# SF32LB57x register map
File version: 1.0
CPU: CM33 r0p1, little endian, MPU, FPU, 3 interrupt priority bits
Registers are 32-bit, read-write, reset 0x0 unless marked. A register's access mark holds for its fields unless they carry their own. Offsets are from the block's base; [hi:lo] are bit positions; {n}, {i} and the like mark numbered series.

## ATIM1
Base 0x50004000
Same registers: ATIM2 0x50005000
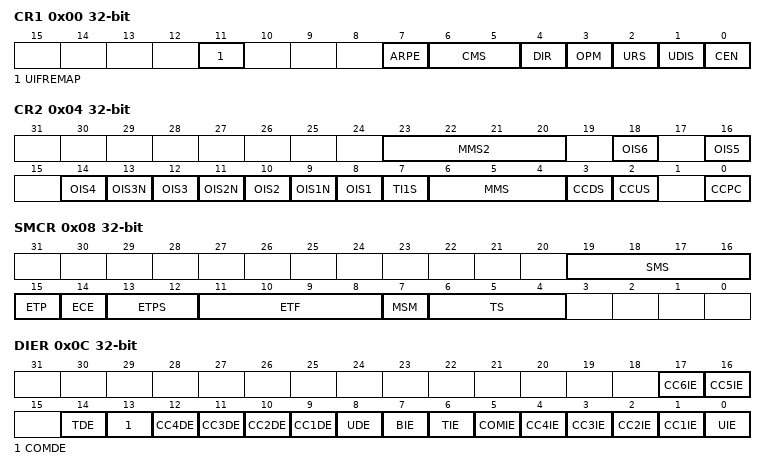
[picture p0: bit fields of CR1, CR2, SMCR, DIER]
0x00 CR1 — TIM control register 1
  [11] UIFREMAP — UIF status bit remapping 0: No remapping. UIF status bit is not copied to TIM_CNT register bit 31 1: Remapping enabled. UIF status bit is copied to TIM_CNT register bit 31.
  [7] ARPE — Auto-reload preload enable 0: TIMx_ARR register is not buffered 1: TIMx_ARR register is buffered
  [6:5] CMS — Center-aligned mode selection 00: Edge-aligned mode. The counter counts up or down depending on the direction bit (DIR). 01: Center-aligned mode 1. The counter counts up and down alternatively. Output compare interrupt flags of channels configured in output (CCxS=00 in TIMx_CCMRx register) are set only when the counter is counting down. 10: Center-aligned mode 2. The counter counts up and down alternatively. Output compare interrupt flags of channels configured in output (CCxS=00 in TIMx_CCMRx register) are set only when the counter is counting up. 11: Center-aligned mode 3. The counter counts up and down alternatively. Output compare interrupt flags of channels configured in output (CCxS=00 in TIMx_CCMRx register) are set both when the counter is counting up or down. Note: It is not allowed to switch from edge-aligned mode to center-aligned mode as long as the counter is enabled (CEN=1)
  [4] DIR — Direction 0: Counter used as upcounter 1: Counter used as downcounter
  [3] OPM — One-pulse mode 0: Counter is not stopped at update event 1: Counter stops counting at the next update event (clearing the bit CEN)
  [2] URS — Update request source This bit is set and cleared by software to select the UEV event sources. 0: Any of the following events generate an update interrupt or DMA request if enabled. These events can be: – Counter overflow/underflow – Setting the UG bit – Update generation through the slave mode controller 1: Only counter overflow/underflow generates an update interrupt or DMA request if enabled.
  [1] UDIS — Update disable This bit is set and cleared by software to enable/disable UEV event generation. 0: UEV enabled. The Update (UEV) event is generated by one of the following events: – Counter overflow/underflow – Setting the UG bit – Update generation through the slave mode controller Buffered registers are then loaded with their preload values. 1: UEV disabled. The Update event is not generated, shadow registers keep their value (ARR, PSC, CCRx). However the counter and the prescaler are reinitialized if the UG bit is set or if a hardware reset is received from the slave mode controller.
  [0] CEN — Counter enable 0: Counter disabled 1: Counter enabled Note: External clock, gated mode and encoder mode can work only if the CEN bit has been previously set by software. However trigger mode can set the CEN bit automatically by hardware. CEN is cleared automatically in one-pulse mode, when an update event occurs.
0x04 CR2 — TIM control register 2
  [23:20] MMS2 — Master mode selection 2 These bits allow the information to be sent to ADC for synchronization (TRGO2) to be selected. The combination is as follows: 0000: Reset - the UG bit from the TIMx_EGR register is used as trigger output (TRGO2). If the reset is generated by the trigger input (slave mode controller configured in reset mode), the signal on TRGO2 is delayed compared to the actual reset. 0001: Enable - the Counter Enable signal CNT_EN is used as trigger output (TRGO2). It is useful to start several timers at the same time or to control a window in which a slave timer is enabled. The Counter Enable signal is generated by a logic AND between the CEN control bit and the trigger input when configured in Gated mode. When the Counter Enable signal is controlled by the trigger input, there is a delay on TRGO2, except if the Master/Slave mode is selected (see the MSM bit description in TIMx_SMCR register). 0010: Update - the update event is selected as trigger output (TRGO2). For instance, a master timer can then be used as a prescaler for a slave timer. 0011: Compare pulse - the trigger output sends a positive pulse when the CC1IF flag is to be set (even if it was already high), as soon as a capture or compare match occurs (TRGO2). 0100: Compare - OC1REFC signal is used as trigger output (TRGO2) 0101: Compare - OC2REFC signal is used as trigger output (TRGO2) 0110: Compare - OC3REFC signal is used as trigger output (TRGO2) 0111: Compare - OC4REFC signal is used as trigger output (TRGO2) 1000: Compare - OC5REF signal is used as trigger output (TRGO2) 1001: Compare - OC6REF signal is used as trigger output (TRGO2) 1010: Compare Pulse - OC4REFC rising or falling edges generate pulses on TRGO2 1011: Compare Pulse - OC6REF rising or falling edges generate pulses on TRGO2 1100: Compare Pulse - OC4REFC or OC6REF rising edges generate pulses on TRGO2 1101: Compare Pulse - OC4REFC rising or OC6REF falling edges generate pulses on TRGO2 1110: Compare Pulse - OC5REF or OC6REF rising edges generate pulses on TRGO2 1111: Compare Pulse - OC5REF rising or OC6REF falling edges generate pulses on TRGO2
  [2n+6] OIS{n} (n=2..6) — Output Idle state {n} (OC{n} output)
  [13] OIS3N — Output Idle state 3 (OC3N output)
  [11] OIS2N — Output Idle state 2 (OC2N output)
  [9] OIS1N — Output Idle state 1 (OC1N output) 0: OC1N=0 after a dead-time when MOE=0 1: OC1N=1 after a dead-time when MOE=0 Note: This bit, as well as other OISxN, can not be modified as long as LOCK level 1, 2 or 3 has been programmed
  [8] OIS1 — Output Idle state 1 (OC1 output) 0: OC1=0 (after a dead-time if OC1N is implemented) when MOE=0 1: OC1=1 (after a dead-time if OC1N is implemented) when MOE=0 Note: This bit, as well as other OISx, can not be modified as long as LOCK level 1, 2 or 3 has been programmed
  [7] TI1S — TI1 selection 0: The TIMx_CH1 pin is connected to TI1 input 1: The TIMx_CH1, CH2 and CH3 pins are connected to the TI1 input (XOR combination)
  [6:4] MMS — Master mode selection These bits allow to select the information to be sent in master mode to slave timers for synchronization (TRGO). The combination is as follows: 000: Reset - the UG bit from the TIMx_EGR register is used as trigger output (TRGO). If the reset is generated by the trigger input (slave mode controller configured in reset mode) then the signal on TRGO is delayed compared to the actual reset. 001: Enable - the Counter enable signal, CNT_EN, is used as trigger output (TRGO). It is useful to start several timers at the same time or to control a window in which a slave timer is enabled. The Counter Enable signal is generated by a logic OR between CEN control bit and the trigger input when configured in gated mode. When the Counter Enable signal is controlled by the trigger input, there is a delay on TRGO, except if the master/slave mode is selected (see the MSM bit description in TIMx_SMCR register). 010: Update - The update event is selected as trigger output (TRGO). For instance a master timer can then be used as a prescaler for a slave timer. 011: Compare Pulse - The trigger output send a positive pulse when the CC1IF flag is to be set (even if it was already high), as soon as a capture or a compare match occurred. (TRGO) 100: Compare - OC1REFC signal is used as trigger output (TRGO) 101: Compare - OC2REFC signal is used as trigger output (TRGO) 110: Compare - OC3REFC signal is used as trigger output (TRGO) 111: Compare - OC4REFC signal is used as trigger output (TRGO) Note: The clock of the slave timer must be enabled prior to receive events from the master timer, and must not be changed on-the-fly while triggers are received from the master timer
  [3] CCDS — Capture/compare DMA selection 0: CCx DMA request sent when CCx event occurs 1: CCx DMA requests sent when update event occurs
  [2] CCUS — Capture/compare control update selection 0: When capture/compare control bits are preloaded (CCPC=1), they are updated by setting the COMG bit only 1: When capture/compare control bits are preloaded (CCPC=1), they are updated by setting the COMG bit or when an edge occurs on TRGI after Trigger selection Note: This bit acts only on channels that have a complementary output.
  [0] CCPC — Capture/compare preloaded control 0: CCxE, CCxNE and OCxM bits are not preloaded 1: CCxE, CCxNE and OCxM bits are preloaded, after having been written, they are updated only when a commutation event (COM) occurs (COMG bit set or edge detected on TRGI after Trigger selection, depending on the CCUS bit). Note: This bit acts only on channels that have a complementary output.
0x08 SMCR — TIM slave mode control register
  [19:16] SMS — Slave mode selection When external signals are selected the active edge of the trigger signal (TRGI) is linked to the polarity selected on the external input (see Input Control register and Control Register description. 0000: Slave mode disabled - if CEN = ‘1 then the prescaler is clocked directly by the internal clock. 0001: Encoder mode 1 - Counter counts up/down on TI1FP1 edge depending on TI2FP2 level. 0010: Encoder mode 2 - Counter counts up/down on TI2FP2 edge depending on TI1FP1 level. 0011: Encoder mode 3 - Counter counts up/down on both TI1FP1 and TI2FP2 edges depending on the level of the other input. 0100: Reset Mode - Rising edge of the selected trigger input (TRGI) reinitializes the counter and generates an update of the registers. 0101: Gated Mode - The counter clock is enabled when the trigger input (TRGI) is high. The counter stops (but is not reset) as soon as the trigger becomes low. Both start and stop of the counter are controlled. 0110: Trigger Mode - The counter starts at a rising edge of the trigger TRGI (but it is not reset). Only the start of the counter is controlled. 0111: External Clock Mode 1 - Rising edges of the selected trigger (TRGI) clock the counter. 1000: Combined reset + trigger mode - Rising edge of the selected trigger input (TRGI) reinitializes the counter, generates an update of the registers and starts the counter. Note: The gated mode must not be used if TI1F_ED is selected as the trigger input (TS=100). Indeed, TI1F_ED outputs 1 pulse for each transition on TI1F, whereas the gated mode checks the level of the trigger signal. Note: The clock of the slave peripherals (timer, ADC, ...) receiving the TRGO or the TRGO2 signals must be enabled prior to receive events from the master timer, and the clock frequency (prescaler) must not be changed on-the-fly while triggers are received from the master timer.
  [15] ETP — External trigger polarity This bit selects whether ETR or ETR is used for trigger operations 0: ETR is non-inverted, active at high level or rising edge 1: ETR is inverted, active at low level or falling edge
  [14] ECE — External clock enable This bit enables External clock mode 2. 0: External clock mode 2 disabled 1: External clock mode 2 enabled. The counter is clocked by any active edge on the ETRF signal. Note: 1: Setting the ECE bit has the same effect as selecting external clock mode 1 with TRGI connected to ETRF (SMS=111 and TS=111). 2: It is possible to simultaneously use external clock mode 2 with the following slave modes: reset mode, gated mode and trigger mode. Nevertheless, TRGI must not be connected to ETRF in this case (TS bits must not be 111). 3: If external clock mode 1 and external clock mode 2 are enabled at the same time, the external clock input is ETRF.
  [13:12] ETPS — External trigger prescaler External trigger signal ETRP frequency must be at most 1/4 of CK_INT frequency. A prescaler can be enabled to reduce ETRP frequency. It is useful when inputting fast external clocks. 00: Prescaler OFF 01: ETRP frequency divided by 2 10: ETRP frequency divided by 4 11: ETRP frequency divided by 8
  [11:8] ETF — External trigger filter This bit-field then defines the frequency used to sample ETRP signal and the length of the digital filter applied to ETRP. The digital filter is made of an event counter in which N consecutive events are needed to validate a transition on the output: 0000: No filter, sampling is done at fpclk 0001: fSAMPLING=fpclk, N=2 0010: fSAMPLING=fpclk, N=4 0011: fSAMPLING=fpclk, N=8 0100: fSAMPLING=fpclk/2, N=6 0101: fSAMPLING=fpclk/2, N=8 0110: fSAMPLING=fpclk/4, N=6 0111: fSAMPLING=fpclk/4, N=8 1000: fSAMPLING=fpclk/8, N=6 1001: fSAMPLING=fpclk/8, N=8 1010: fSAMPLING=fpclk/16, N=5 1011: fSAMPLING=fpclk/16, N=6 1100: fSAMPLING=fpclk/16, N=8 1101: fSAMPLING=fpclk/32, N=5 1110: fSAMPLING=fpclk/32, N=6 1111: fSAMPLING=fpclk/32, N=8
  [7] MSM — Master/Slave mode 0: No action 1: The effect of an event on the trigger input (TRGI) is delayed to allow a perfect synchronization between the current timer and its slaves (through TRGO). It is useful if we want to synchronize several timers on a single external event.
  [6:4] TS — Trigger selection This bit-field selects the trigger input to be used to synchronize the counter. 000: Internal Trigger 0 (ITR0) 001: Internal Trigger 1 (ITR1) 010: Internal Trigger 2 (ITR2) 011: Internal Trigger 3 (ITR3) 100: TI1 Edge Detector (TI1F_ED) 101: Filtered Timer Input 1 (TI1FP1) 110: Filtered Timer Input 2 (TI2FP2) 111: External Trigger input (ETRF) Note: These bits must be changed only when they are not used (e.g. when SMS=000) to avoid wrong edge detections at the transition.
0x0C DIER — TIM DMA/Interrupt enable register
  [17] CC6IE — Capture/Compare 6 interrupt enable 0: CC6 interrupt disabled. 1: CC6 interrupt enabled
  [16] CC5IE — Capture/Compare 5 interrupt enable 0: CC5 interrupt disabled. 1: CC5 interrupt enabled
  [14] TDE — Trigger DMA request enable 0: Trigger DMA request disabled. 1: Trigger DMA request enabled.
  [13] COMDE — COM DMA request enable 0: COM DMA request disabled 1: COM DMA request enabled
  [12] CC4DE — Capture/Compare 4 DMA request enable 0: CC4 DMA request disabled. 1: CC4 DMA request enabled
  [11] CC3DE — Capture/Compare 3 DMA request enable 0: CC3 DMA request disabled. 1: CC3 DMA request enabled.
  [10] CC2DE — Capture/Compare 2 DMA request enable 0: CC2 DMA request disabled. 1: CC2 DMA request enabled.
  [9] CC1DE — Capture/Compare 1 DMA request enable 0: CC1 DMA request disabled. 1: CC1 DMA request enabled.
  [8] UDE — Update DMA request enable 0: Update DMA request disabled. 1: Update DMA request enabled
  [7] BIE — Break interrupt enable 0: Break interrupt disabled 1: Break interrupt enabled
  [6] TIE — Trigger interrupt enable 0: Trigger interrupt disabled. 1: Trigger interrupt enabled
  [5] COMIE — COM interrupt enable 0: COM interrupt disabled 1: COM interrupt enabled
  [4] CC4IE — Capture/Compare 4 interrupt enable 0: CC4 interrupt disabled. 1: CC4 interrupt enabled
  [3] CC3IE — Capture/Compare 3 interrupt enable 0: CC3 interrupt disabled. 1: CC3 interrupt enabled
  [2] CC2IE — Capture/Compare 2 interrupt enable 0: CC2 interrupt disabled. 1: CC2 interrupt enabled.
  [1] CC1IE — Capture/Compare 1 interrupt enable 0: CC1 interrupt disabled. 1: CC1 interrupt enabled
  [0] UIE — Update interrupt enable 0: Update interrupt disabled. 1: Update interrupt enabled
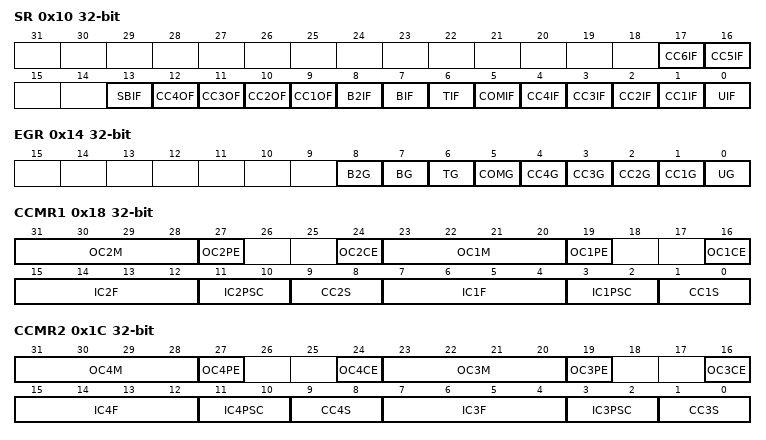
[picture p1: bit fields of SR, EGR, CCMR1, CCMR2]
0x10 SR — TIM status register
  [17] CC6IF — Compare 6 interrupt flag
  [16] CC5IF — Compare 5 interrupt flag
  [13] SBIF — System Break interrupt flag This flag is set by hardware as soon as the system break input goes active. It can be cleared by software if the system break input is not active. This flag must be reset to re-start PWM operation. 0: No break event occurred. 1: An active level has been detected on the system break input. An interrupt is generated if BIE=1 in the TIMx_DIER register.
  [12] CC4OF — Capture/Compare 4 overcapture flag
  [11] CC3OF — Capture/Compare 3 overcapture flag
  [10] CC2OF — Capture/Compare 2 overcapture flag
  [9] CC1OF — Capture/Compare 1 overcapture flag This flag is set by hardware only when the corresponding channel is configured in input capture mode. It is cleared by software by writing it to ‘0’. 0: No overcapture has been detected. 1: The counter value has been captured in TIMx_CCR1 register while CC1IF flag was already set
  [8] B2IF — Break 2 interrupt flag This flag is set by hardware as soon as the break 2 input goes active. It can be cleared by software if the break 2 input is not active. 0: No break event occurred. 1: An active level has been detected on the break 2 input. An interrupt is generated if BIE=1 in the TIMx_DIER register.
  [7] BIF — Break interrupt flag This flag is set by hardware as soon as the break input goes active. It can be cleared by software if the break input is not active. 0: No break event occurred. 1: An active level has been detected on the break input. An interrupt is generated if BIE=1 in the TIMx_DIER register.
  [6] TIF — Trigger interrupt flag This flag is set by hardware on trigger event (active edge detected on TRGI input when the slave mode controller is enabled in all modes but gated mode. It is set when the counter starts or stops when gated mode is selected. It is cleared by software. 0: No trigger event occurred. 1: Trigger interrupt pending.
  [5] COMIF — COM interrupt flag This flag is set by hardware on COM event (when Capture/compare Control bits - CCxE, CCxNE, OCxM - have been updated). It is cleared by software. 0: No COM event occurred. 1: COM interrupt pending.
  [4] CC4IF — Capture/Compare 4 interrupt flag
  [3] CC3IF — Capture/Compare 3 interrupt flag
  [2] CC2IF — Capture/Compare 2 interrupt flag
  [1] CC1IF — Capture/Compare 1 interrupt flag If channel CC1 is configured as output: This flag is set by hardware when the counter matches the compare value, with some exception in center-aligned mode (refer to the CMS bits in the TIMx_CR1 register description) and in retriggerable one pulse mode. It is cleared by software. 0: No match. 1: The content of the counter TIMx_CNT has matched the content of the TIMx_CCR1 register. If channel CC1 is configured as input: This bit is set by hardware on a capture. It is cleared by software or by reading the TIMx_CCR1 register. 0: No input capture occurred. 1: The counter value has been captured in TIMx_CCR1 register (An edge has been detected on IC1 which matches the selected polarity).
  [0] UIF — Update interrupt flag This bit is set by hardware on an update event. It is cleared by software. 0: No update occurred 1: Update interrupt pending. This bit is set by hardware when the registers are updated: - At overflow or underflow regarding the repetition counter value (update if repetition counter = 0) and if UDIS=0 in the TIMx_CR1 register. - When CNT is reinitialized by software using the UG bit in TIMx_EGR register, if URS=0 and UDIS=0 in the TIMx_CR1 register. - When CNT is reinitialized by a trigger event, if URS=0 and UDIS=0 in the TIMx_CR1 register.
0x14 EGR — Event generation register
  [8] B2G — Break 2 generation This bit is set by software in order to generate an event, it is automatically cleared by hardware. 0: No action 1: A break 2 event is generated. MOE bit is cleared and B2IF flag is set. Related interrupt can occur if enabled.
  [7] BG — Break generation This bit is set by software in order to generate an event, it is automatically cleared by hardware. 0: No action 1: A break event is generated. MOE bit is cleared and BIF flag is set. Related interrupt or DMA transfer can occur if enabled.
  [6] TG — Trigger generation This bit is set by software in order to generate an event, it is automatically cleared by hardware. 0: No action 1: The TIF flag is set in TIMx_SR register. Related interrupt or DMA transfer can occur if enabled.
  [5] COMG — Capture/Compare control update generation This bit can be set by software, it is automatically cleared by hardware 0: No action 1: When CCPC bit is set, it allows to update CCxE, CCxNE and OCxM bits Note: This bit acts only on channels having a complementary output.
  [4] CC4G — Capture/compare 4 generation
  [3] CC3G — Capture/compare 3 generation
  [2] CC2G — Capture/compare 2 generation
  [1] CC1G — Capture/compare 1 generation This bit is set by software in order to generate an event, it is automatically cleared by hardware. 0: No action 1: A capture/compare event is generated on channel 1: If channel CC1 is configured as output: CC1IF flag is set, Corresponding interrupt or DMA request is sent if enabled. If channel CC1 is configured as input: The current value of the counter is captured in TIMx_CCR1 register. The CC1IF flag is set, the corresponding interrupt or DMA request is sent if enabled. The CC1OF flag is set if the CC1IF flag was already high.
  [0] UG — Update generation This bit can be set by software, it is automatically cleared by hardware. 0: No action 1: Re-initialize the counter and generates an update of the registers. Note that the prescaler counter is cleared too (anyway the prescaler ratio is not affected). The counter is cleared if the center-aligned mode is selected or if DIR=0 (upcounting), else it takes the auto-reload value (TIMx_ARR) if DIR=1 (downcounting).
0x18 CCMR1 — TIM capture/compare mode register 1
  [31:28] OC2M — Output compare 2 mode
  [27] OC2PE — Output compare 2 preload enable
  [24] OC2CE — Output compare 2 clear enable
  [23:20] OC1M — Output compare 1 mode These bits define the behavior of the output reference signal OC1REF from which OC1 and OC1N are derived. OC1REF is active high whereas OC1 and OC1N active level depends on CC1P and CC1NP bits. 0000: Frozen - The comparison between the output compare register TIMx_CCR1 and the counter TIMx_CNT has no effect on the outputs.(this mode is used to generate a timing base). 0001: Set channel 1 to active level on match. OC1REF signal is forced high when the counter TIMx_CNT matches the capture/compare register 1 (TIMx_CCR1). 0010: Set channel 1 to inactive level on match. OC1REF signal is forced low when the counter TIMx_CNT matches the capture/compare register 1 (TIMx_CCR1). 0011: Toggle - OC1REF toggles when TIMx_CNT=TIMx_CCR1. 0100: Force inactive level - OC1REF is forced low. 0101: Force active level - OC1REF is forced high. 0110: PWM mode 1 - In upcounting, channel 1 is active as long as TIMx_CNTltTIMx_CCR1 else inactive. In downcounting, channel 1 is inactive (OC1REF=‘0) as long as TIMx_CNT>TIMx_CCR1 else active (OC1REF=1). 0111: PWM mode 2 - In upcounting, channel 1 is inactive as long as TIMx_CNTltTIMx_CCR1 else active. In downcounting, channel 1 is active as long as TIMx_CNT>TIMx_CCR1 else inactive. 1000: Retriggerable OPM mode 1 - In up-counting mode, the channel is active until a trigger event is detected (on TRGI signal). Then, a comparison is performed as in PWM mode 1 and the channels becomes inactive again at the next update. In down-counting mode, the channel is inactive until a trigger event is detected (on TRGI signal). Then, a comparison is performed as in PWM mode 1 and the channels becomes inactive again at the next update. 1001: Retriggerable OPM mode 2 - In up-counting mode, the channel is inactive until a trigger event is detected (on TRGI signal). Then, a comparison is performed as in PWM mode 2 and the channels becomes inactive again at the next update. In down-counting mode, the channel is active until a trigger event is detected (on TRGI signal). Then, a comparison is performed as in PWM mode 1 and the channels becomes active again at the next update. 1010: Reserved, 1011: Reserved, 1100: Combined PWM mode 1 - OC1REF has the same behavior as in PWM mode 1. OC1REFC is the logical OR between OC1REF and OC2REF. 1101: Combined PWM mode 2 - OC1REF has the same behavior as in PWM mode 2. OC1REFC is the logical AND between OC1REF and OC2REF. 1110: Asymmetric PWM mode 1 - OC1REF has the same behavior as in PWM mode 1. OC1REFC outputs OC1REF when the counter is counting up, OC2REF when it is counting down. 1111: Asymmetric PWM mode 2 - OC1REF has the same behavior as in PWM mode 2. OC1REFC outputs OC1REF when the counter is counting up, OC2REF when it is counting down. Note: These bits can not be modified as long as LOCK level 3 has been programmed and CC1S=’00’ (the channel is configured in output). Note: On channels having a complementary output, this bit field is preloaded. If the CCPC bit is set in the TIMx_CR2 register then the OC1M active bits take the new value from the preloaded bits only when a COM event is generated.
  [19] OC1PE — Output compare 1 preload enable 0: Preload register on TIMx_CCR1 disabled. TIMx_CCR1 can be written at anytime, the new value is taken in account immediately. 1: Preload register on TIMx_CCR1 enabled. Read/Write operations access the preload register. TIMx_CCR1 preload value is loaded in the active register at each update event. Note: These bits can not be modified as long as LOCK level 3 has been programmed and CC1S=’00’ (the channel is configured in output).
  [16] OC1CE — Output compare 1 clear enable 0: OC1Ref is not affected by the ETRF input 1: OC1Ref is cleared as soon as a High level is detected on ETRF input
  [15:12] IC2F — Input capture 2 filter
  [11:10] IC2PSC — Input capture 2 prescaler
  [9:8] CC2S — Capture/Compare 2 selection This bit-field defines the direction of the channel (input/output) as well as the used input. 00: CC2 channel is configured as output 01: CC2 channel is configured as input, IC2 is mapped on TI2 10: CC2 channel is configured as input, IC2 is mapped on TI1 11: CC2 channel is configured as input, IC2 is mapped on TRC. This mode is working only if an internal trigger input is selected through the TS bit (TIMx_SMCR register)
  [7:4] IC1F — Input capture 1 filter This bit-field defines the frequency used to sample TI1 input and the length of the digital filter applied to TI1. The digital filter is made of an event counter in which N consecutive events are needed to validate a transition on the output: 0000: No filter, sampling is done at fpclk 0001: fSAMPLING=fpclk, N=2 0010: fSAMPLING=fpclk, N=4 0011: fSAMPLING=fpclk, N=8 0100: fSAMPLING=fpclk/2, N=6 0101: fSAMPLING=fpclk/2, N=8 0110: fSAMPLING=fpclk/4, N=6 0111: fSAMPLING=fpclk/4, N=8 1000: fSAMPLING=fpclk/8, N=6 1001: fSAMPLING=fpclk/8, N=8 1010: fSAMPLING=fpclk/16, N=5 1011: fSAMPLING=fpclk/16, N=6 1100: fSAMPLING=fpclk/16, N=8 1101: fSAMPLING=fpclk/32, N=5 1110: fSAMPLING=fpclk/32, N=6 1111: fSAMPLING=fpclk/32, N=8
  [3:2] IC1PSC — Input capture 1 prescaler This bit-field defines the ratio of the prescaler acting on CC1 input (IC1). The prescaler is reset as soon as CC1E=0 (TIMx_CCER register). 00: no prescaler, capture is done each time an edge is detected on the capture input 01: capture is done once every 2 events 10: capture is done once every 4 events 11: capture is done once every 8 events
  [1:0] CC1S — Capture/Compare 1 selection This bit-field defines the direction of the channel (input/output) as well as the used input. 00: CC1 channel is configured as output 01: CC1 channel is configured as input, IC1 is mapped on TI1 10: CC1 channel is configured as input, IC1 is mapped on TI2 11: CC1 channel is configured as input, IC1 is mapped on TRC. This mode is working only if an internal trigger input is selected through TS bit (TIMx_SMCR register)
0x1C CCMR2 — TIM capture/compare mode register 2
  [31:28] OC4M — Output compare 4 mode
  [27] OC4PE — Output compare 4 preload enable
  [24] OC4CE — Output compare 4 clear enable
  [23:20] OC3M — Output compare 3 mode
  [19] OC3PE — Output compare 3 preload enable
  [16] OC3CE — Output compare 3 clear enable
  [15:12] IC4F — Input capture 4 filter
  [11:10] IC4PSC — Input capture 4 prescaler
  [9:8] CC4S — Capture/Compare 4 selection This bit-field defines the direction of the channel (input/output) as well as the used input. 00: CC4 channel is configured as output 01: CC4 channel is configured as input, IC4 is mapped on TI4 10: CC4 channel is configured as input, IC4 is mapped on TI3 11: CC4 channel is configured as input, IC4 is mapped on TRC. This mode is working only if an internal trigger input is selected through TS bit (TIMx_SMCR register)
  [7:4] IC3F — Input capture 3 filter
  [3:2] IC3PSC — Input capture 3 prescaler
  [1:0] CC3S — Capture/Compare 3 selection This bit-field defines the direction of the channel (input/output) as well as the used input. 00: CC3 channel is configured as output 01: CC3 channel is configured as input, IC3 is mapped on TI3 10: CC3 channel is configured as input, IC3 is mapped on TI4 11: CC3 channel is configured as input, IC3 is mapped on TRC. This mode is working only if an internal trigger input is selected through TS bit (TIMx_SMCR register)
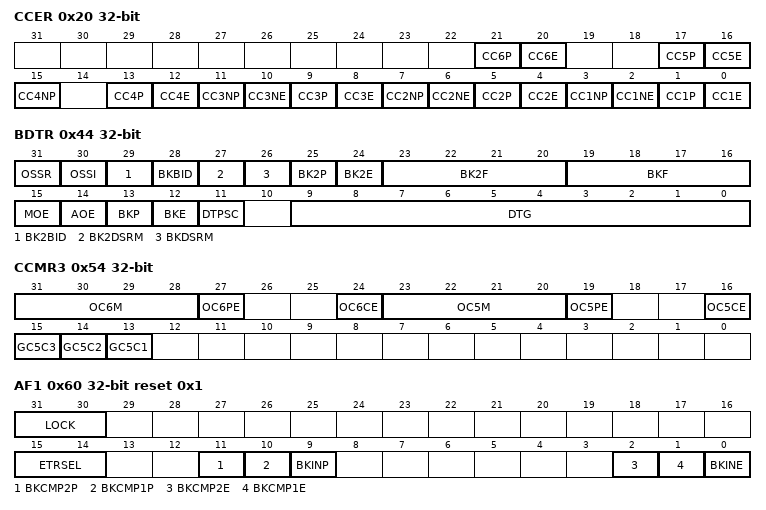
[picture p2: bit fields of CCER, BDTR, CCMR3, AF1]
0x20 CCER — Capture/Compare enable register
  [4n-3] CC{n}P (n=2..6) — Capture/Compare {n} output Polarity.
  [4n-4] CC{n}E (n=2..6) — Capture/Compare {n} output enable.
  [15] CC4NP — Capture/Compare 4 complementary output polarity
  [11] CC3NP — Capture/Compare 3 complementary output polarity
  [10] CC3NE — Capture/Compare 3 complementary output enable
  [7] CC2NP — Capture/Compare 2 complementary output polarity
  [6] CC2NE — Capture/Compare 2 complementary output enable
  [3] CC1NP — Capture/Compare 1 complementary output polarity CC1 channel configured as output: 0: OC1N active high. 1: OC1N active low. CC1 channel configured as input: This bit is used in conjunction with CC1P to define the polarity of TI1FP1 and TI2FP1. Refer to CC1P description. On channels having a complementary output, this bit is preloaded. If the CCPC bit is set in the TIMx_CR2 register then the CC1NP active bit takes the new value from the preloaded bit only when a Commutation event is generated. Note: This bit as well as other CCxNP is not writable as soon as LOCK level 2 or 3 has been programmed and CC1S=”00” (channel configured as output).
  [2] CC1NE — Capture/Compare 1 complementary output enable 0: Off - OC1N is not active. OC1N level is then function of MOE, OSSI, OSSR, OIS1, OIS1N and CC1E bits. 1: On - OC1N signal is output on the corresponding output pin depending on MOE, OSSI, OSSR, OIS1, OIS1N and CC1E bits. On channels having a complementary output, this bit is preloaded. If the CCPC bit is set in the TIMx_CR2 register then the CC1NE active bit takes the new value from the preloaded bit only when a Commutation event is generated.
  [1] CC1P — Capture/Compare 1 output Polarity. CC1 channel configured as output: 0: OC1 active high 1: OC1 active low CC1 channel configured as input: CC1NP/CC1P bits select TI1FP1 and TI2FP1 polarity for trigger or capture operations. 00: noninverted/rising edge. Circuit is sensitive to TIxFP1 rising edge (capture, trigger in reset, external clock or trigger mode), TIxFP1 is not inverted (trigger in gated mode, encoder mode). 01: inverted/falling edge. Circuit is sensitive to TIxFP1 falling edge (capture, trigger in reset, external clock or trigger mode), TIxFP1 is inverted (trigger in gated mode, encoder mode). 10: reserved, do not use this configuration. 11: noninverted/both edges. Circuit is sensitive to both TIxFP1 rising and falling edges (capture, trigger in reset, external clock or trigger mode), TIxFP1 is not inverted (trigger in gated mode). This configuration must not be used for encoder mode. On channels having a complementary output, this bit is preloaded. If the CCPC bit is set in the TIMx_CR2 register then the CC1P active bit takes the new value from the preloaded bit only when a Commutation event is generated. Note: This bit as well as other CCxP is not writable as soon as LOCK level 2 or 3 has been programmed.
  [0] CC1E — Capture/Compare 1 output enable CC1 channel configured as output: 0: Off - OC1 is not active. OC1 level is then function of MOE, OSSI, OSSR, OIS1, OIS1N and CC1NE bits. 1: On - OC1 signal is output on the corresponding output pin depending on MOE, OSSI, OSSR, OIS1, OIS1N and CC1NE bits. CC1 channel configured as input: This bit determines if a capture of the counter value can actually be done into the input capture/compare register 1 (TIMx_CCR1) or not. 0: Capture disabled. 1: Capture enabled. On channels having a complementary output, this bit is preloaded. If the CCPC bit is set in the TIMx_CR2 register then the CC1E active bit takes the new value from the preloaded bit only when a Commutation event is generated.
0x24 CNT — Counter
  [31:0] CNT — bit 30 to 0 is the lower bits of counter value bit 31 depends on IUFREMAP in TIMx_CR1. If UIFREMAP = 1 this bit is a read-only copy of the UIF bit of the TIMx_ISR register If UIFREMAP = 0 this bit is counter value bit 31
0x28 PSC — Prescaler
  [15:0] PSC — Prescaler value The counter clock frequency is fpclk/(PSC+1). PSC contains the value to be loaded in the active prescaler register at each update event (including when the counter is cleared through UG bit of TIMx_EGR register or through trigger controller when configured in “reset mode”).
0x2C ARR — Auto-reload register
  [31:0] ARR — Auto-reload value ARR is the value to be loaded in the actual auto-reload register.
0x30 RCR — Repetition counter register
  [15:0] REP — Repetition counter value These bits allow the user to set-up the update rate of the compare registers (i.e. periodic transfers from preload to active registers) when preload registers are enable, as well as the update interrupt generation rate, if this interrupt is enable. Each time the REP_CNT related downcounter reaches zero, an update event is generated and it restarts counting from REP value. As REP_CNT is reloaded with REP value only at the repetition update event, any write to the TIMx_RCR register is not taken in account until the next repetition update event. It means in PWM mode (REP+1) corresponds to the number of PWM periods in edge-aligned mode or the number of half PWM period in center-aligned mode..
0x34 CCR1 — Capture/Compare register 1
  [31:0] CCR1 — Capture/Compare 1 value If channel CC1 is configured as output: CCR1 is the value to be loaded in the actual capture/compare 1 register (preload value).It is loaded permanently if the preload feature is not selected in the TIMx_CCMR1 register (bit OC1PE). Else the preload value is copied in the active capture/compare 1 register when an update event occurs. The active capture/compare register contains the value to be compared to the counter TIMx_CNT and signaled on OC1 output. If channel CC1is configured as input: CCR1 is the counter value transferred by the last input capture 1 event (IC1).
0x38 CCR2 — Capture/Compare register 2
  [31:0] CCR2 — Capture/Compare 2 value If channel CC2 is configured as output: CCR2 is the value to be loaded in the actual capture/compare 2 register (preload value).It is loaded permanently if the preload feature is not selected in the TIMx_CCMR1 register (bit OC2PE). Else the preload value is copied in the active capture/compare 2 register when an update event occurs. The active capture/compare register contains the value to be compared to the counter TIMx_CNT and signalled on OC2 output. If channel CC2 is configured as input: CCR2 is the counter value transferred by the last input capture 2 event (IC2).
0x3C CCR3 — Capture/Compare register 3
  [31:0] CCR3 — Capture/Compare value If channel CC3 is configured as output: CCR3 is the value to be loaded in the actual capture/compare 3 register (preload value).It is loaded permanently if the preload feature is not selected in the TIMx_CCMR2 register (bit OC3PE). Else the preload value is copied in the active capture/compare 3 register when an update event occurs. The active capture/compare register contains the value to be compared to the counter TIMx_CNT and signalled on OC3 output. If channel CC3is configured as input: CCR3 is the counter value transferred by the last input capture 3 event (IC3).
0x40 CCR4 — Capture/Compare register 4
  [31:0] CCR4 — Capture/Compare value 1. if CC4 channel is configured as output (CC4S bits): CCR4 is the value to be loaded in the actual capture/compare 4 register (preload value).It is loaded permanently if the preload feature is not selected in the TIMx_CCMR2 register (bit OC4PE). Else the preload value is copied in the active capture/compare 4 register when an update event occurs. The active capture/compare register contains the value to be compared to the counter TIMx_CNT and signalled on OC4 output. 2. if CC4 channel is configured as input (CC4S bits in TIMx_CCMR4 register): CCR4 is the counter value transferred by the last input capture 4 event (IC4).
0x44 BDTR — TIM break and dead-time register
  [31] OSSR — Off-state selection for Run mode This bit is used when MOE=1 on channels having a complementary output which are configured as outputs. OSSR is not implemented if no complementary output is implemented in the timer. 0: When inactive, OC/OCN outputs are disabled (the timer releases the output control which is taken over by the GPIO logic, which forces a Hi-Z state). 1: When inactive, OC/OCN outputs are enabled with their inactive level as soon as CCxE=1 or CCxNE=1 (the output is still controlled by the timer). Note: This bit can not be modified as soon as the LOCK level 2 has been programmed.
  [30] OSSI — Off-state selection for Idle mode This bit is used when MOE=0 due to a break event or by a software write, on channels configured as outputs. 0: When inactive, OC/OCN outputs are disabled (the timer releases the output control which is taken over by the GPIO logic and which imposes a Hi-Z state). 1: When inactive, OC/OCN outputs are first forced with their inactive level then forced to their idle level after the deadtime. The timer maintains its control over the output. Note: This bit can not be modified as soon as the LOCK level 2 has been programmed.
  [29] BK2BID — Break2 bidirectional
  [28] BKBID — Break Bidirectional 0: Break input BRK in input mode 1: Break input BRK in bidirectional mode In the bidirectional mode (BKBID bit set to 1), the break input is configured both in input mode and in open drain output mode. Any active break event asserts a low logic level on the Break input to indicate an internal break event to external devices. Note: This bit cannot be modified as long as LOCK level 1 has been programmed (LOCK bits in TIMx_BDTR register).
  [27] BK2DSRM — Break2 Disarm
  [26] BKDSRM — Break Disarm 0: Break input BRK is armed 1: Break input BRK is disarmed This bit is cleared by hardware when no break source is active. The BKDSRM bit must be set by software to release the bidirectional output control (open-drain output in Hi-Z state) and then be polled it until it is reset by hardware, indicating that the fault condition has disappeared.
  [25] BK2P — BK2P: Break 2 polarity 0: Break input BRK2 is active low 1: Break input BRK2 is active high Note: This bit cannot be modified as long as LOCK level 1 has been programmed.
  [24] BK2E — Break 2 enable This bit enables the complete break 2 protection. 0: Break2 function disabled 1: Break2 function enabled Note: This bit cannot be modified as long as LOCK level 1 has been programmed.
  [23:20] BK2F — Break 2 filter This bit-field defines the frequency used to sample BRK2 input and the length of the digital filter applied to BRK2. The digital filter is made of an event counter in which N consecutive events are needed to validate a transition on the output: 0000: No filter, BRK2 acts asynchronously 0001: fSAMPLING=fpclk, N=2 0010: fSAMPLING=fpclk, N=4 0011: fSAMPLING=fpclk, N=8 0100: fSAMPLING=fpclk/2, N=6 0101: fSAMPLING=fpclk/2, N=8 0110: fSAMPLING=fpclk/4, N=6 0111: fSAMPLING=fpclk/4, N=8 1000: fSAMPLING=fpclk/8, N=6 1001: fSAMPLING=fpclk/8, N=8 1010: fSAMPLING=fpclk/16, N=5 1011: fSAMPLING=fpclk/16, N=6 1100: fSAMPLING=fpclk/16, N=8 1101: fSAMPLING=fpclk/32, N=5 1110: fSAMPLING=fpclk/32, N=6 1111: fSAMPLING=fpclk/32, N=8 Note: This bit cannot be modified as long as LOCK level 1 has been programmed.
  [19:16] BKF — Break filter This bit-field defines the frequency used to sample BRK input and the length of the digital filter applied to BRK. The digital filter is made of an event counter in which N consecutive events are needed to validate a transition on the output: 0000: No filter, BRK acts asynchronously 0001: fSAMPLING=fpclk, N=2 0010: fSAMPLING=fpclk, N=4 0011: fSAMPLING=fpclk, N=8 0100: fSAMPLING=fpclk/2, N=6 0101: fSAMPLING=fpclk/2, N=8 0110: fSAMPLING=fpclk/4, N=6 0111: fSAMPLING=fpclk/4, N=8 1000: fSAMPLING=fpclk/8, N=6 1001: fSAMPLING=fpclk/8, N=8 1010: fSAMPLING=fpclk/16, N=5 1011: fSAMPLING=fpclk/16, N=6 1100: fSAMPLING=fpclk/16, N=8 1101: fSAMPLING=fpclk/32, N=5 1110: fSAMPLING=fpclk/32, N=6 1111: fSAMPLING=fpclk/32, N=8 Note: This bit cannot be modified as long as LOCK level 1 has been programmed.
  [15] MOE — Main output enable This bit is cleared asynchronously by hardware as soon as one of the break inputs is active (BRK or BRK2). It is set by software or automatically depending on the AOE bit. It is acting only on the channels which are configured in output. 0: In response to a break 2 event. OC and OCN outputs are disabled In response to a break event or if MOE is written to 0: OC and OCN outputs are disabled or forced to idle state depending on the OSSI bit. 1: OC and OCN outputs are enabled if their respective enable bits are set (CCxE, CCxNE in TIMx_CCER register).
  [14] AOE — Automatic output enable 0: MOE can be set only by software 1: MOE can be set by software or automatically at the next update event (if none of the break inputs BRK and BRK2 is active) Note: This bit cannot be modified as long as LOCK level 1 has been programmed.
  [13] BKP — Break polarity 0: Break input BRK is active low 1: Break input BRK is active high Note: This bit cannot be modified as long as LOCK level 1 has been programmed.
  [12] BKE — Break enable This bit enables the complete break protection (including all sources connected to bk_acth and BKIN sources). 0: Break function disabled 1: Break function enabled Note: This bit cannot be modified as long as LOCK level 1 has been programmed.
  [11] DTPSC — Dead-time prescaler This bit-field enables dead-time prescaler. 0: dead-time is Tpclk*(DTG+1) if DTG is not zero 1: dead-time is Tpclk*(DTG+1)*16 if DTG is not zero Note: This bit cannot be modified as long as LOCK level 1 has been programmed.
  [9:0] DTG — Dead-time generator setup This bit-field, together with DTPSC, defines the duration of the dead-time inserted between the complementary outputs. If DTG=0, dead-time is disabled. Example if Tpclk=8.33ns (120MHz), dead-time possible values are: 16.67ns to 8533.33 ns by 8.33 ns steps if DTPSC=0, 266.67ns to 136.53 us by 133.33 ns steps if DTPSC=1 Note: This bit cannot be modified as long as LOCK level 1 has been programmed.
0x54 CCMR3 — TIM capture/compare mode register 3
  [31:28] OC6M — Output compare 6 mode
  [27] OC6PE — Output compare 6 preload enable
  [24] OC6CE — Output compare 6 clear enable
  [23:20] OC5M — Output compare 5 mode
  [19] OC5PE — Output compare 5 preload enable
  [16] OC5CE — Output compare 5 clear enable
  [15] GC5C3 — Group Channel 5 and Channel 3 Distortion on Channel 3 output: 0: No effect of OC5REF on OC3REFC 1: OC3REFC is the logical AND of OC3REFC and OC5REF This bit can either have immediate effect or be preloaded and taken into account after an update event (if preload feature is selected in TIMxCCMR2).
  [14] GC5C2 — Group Channel 5 and Channel 2 Distortion on Channel 2 output: 0: No effect of OC5REF on OC2REFC 1: OC2REFC is the logical AND of OC2REFC and OC5REF This bit can either have immediate effect or be preloaded and taken into account after an update event (if preload feature is selected in TIMxCCMR1).
  [13] GC5C1 — Group Channel 5 and Channel 1 Distortion on Channel 1 output: 0: No effect of OC5REF on OC1REFC5 1: OC1REFC is the logical AND of OC1REFC and OC5REF This bit can either have immediate effect or be preloaded and taken into account after an update event (if preload feature is selected in TIMxCCMR1).
0x58 CCR5 — Capture/Compare register 5
  [31:0] CCR5 — Capture/Compare 5 value CCR5 is the value to be loaded in the actual capture/compare 5 register (preload value). It is loaded permanently if the preload feature is not selected in the TIMx_CCMR3 register (bit OC5PE). Else the preload value is copied in the active capture/compare 5 register when an update event occurs. The active capture/compare register contains the value to be compared to the counter TIMx_CNT and signaled on OC5 output.
0x5C CCR6 — Capture/Compare register 6
  [31:0] CCR6 — Capture/Compare 6 value CCR6 is the value to be loaded in the actual capture/compare 6 register (preload value). It is loaded permanently if the preload feature is not selected in the TIMx_CCMR3 register (bit OC6PE). Else the preload value is copied in the active capture/compare 6 register when an update event occurs. The active capture/compare register contains the value to be compared to the counter TIMx_CNT and signaled on OC6 output.
0x60 AF1 reset 0x1 — Alternate function option register
  [31:30] LOCK — Lock configuration These bits offer a write protection against software errors. 00: LOCK OFF - No bit is write protected. 01: LOCK Level 1 = OISx and OISxN bits in TIMx_CR2 register, BK2BID, BKBID, BK2DSRM, BKDSRM, BK2P, BK2E, BK2F[3:0], BKF[3:0], AOE, BKP, BKE, OSSI, OSSR, DTPSC and DTG bits in TIMx_BDTR register, TIMx_AF1 register and TIMx_AF2 register can no longer be written. 10: LOCK Level 2 = LOCK Level 1 + CC Polarity bits (CCxP/CCxNP bits in TIMx_CCER register, as long as the related channel is configured in output through the CCxS bits) as well as OSSR and OSSI bits can no longer be written. 11: LOCK Level 3 = LOCK Level 2 + CC Control bits (OCxM and OCxPE bits in TIMx_CCMRx registers, as long as the related channel is configured in output through the CCxS bits) can no longer be written. Note: The LOCK bits can be written to non-zero only once after reset.
  [15:14] ETRSEL — ETR source selection 00: ETR input is connected to I/O 01: COMP1 output 10: COMP2 output 11: Reserved Note: This bit cannot be modified as long as LOCK level 1 has been programmed.
  [11] BKCMP2P — BRK COMP2 input polarity This bit selects the COMP2 input sensitivity. It must be programmed together with the BKP polarity bit. 0: COMP2 input is active high 1: COMP2 input is active low Note: This bit cannot be modified as long as LOCK level 1 has been programmed.
  [10] BKCMP1P — BRK COMP1 input polarity This bit selects the COMP1 input sensitivity. It must be programmed together with the BKP polarity bit. 0: COMP1 input is active high 1: COMP1 input is active low Note: This bit cannot be modified as long as LOCK level 1 has been programmed.
  [9] BKINP — BRK BKIN input polarity This bit selects the BKIN input sensitivity. It must be programmed together with the BKP polarity bit. 0: BKIN input is active high 1: BKIN input is active low Note: This bit cannot be modified as long as LOCK level 1 has been programmed.
  [2] BKCMP2E — BRK COMP2 enable This bit enables the COMP2 for the timer’s BRK input. COMP2 output is ‘ORed’ with the other BRK sources. 0: COMP2 input disabled 1: COMP2 input enabled Note: This bit cannot be modified as long as LOCK level 1 has been programmed.
  [1] BKCMP1E — BRK COMP1 enable This bit enables the COMP1 for the timer’s BRK input. COMP1 output is ‘ORed’ with the other BRK sources. 0: COMP1 input disabled 1: COMP1 input enabled Note: This bit cannot be modified as long as LOCK level 1 has been programmed.
  [0] BKINE — BRK BKIN input enable This bit enables the BKIN input. BKIN input is ‘ORed’ with the other BRK sources. 0: BKIN input disabled 1: BKIN input enabled Note: This bit cannot be modified as long as LOCK level 1 has been programmed.
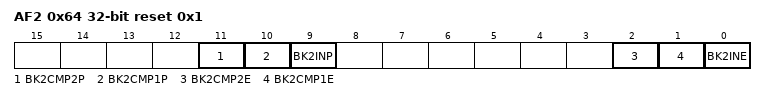
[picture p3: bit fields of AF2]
0x64 AF2 reset 0x1 — Alternate function option register 2
  [11] BK2CMP2P — BRK2 COMP2 input polarity This bit selects the COMP2 input sensitivity. It must be programmed together with the BK2P polarity bit. 0: COMP2 input is active low 1: COMP2 input is active high Note: This bit cannot be modified as long as LOCK level 1 has been programmed.
  [10] BK2CMP1P — BRK2 COMP1 input polarity This bit selects the COMP1 input sensitivity. It must be programmed together with the BK2P polarity bit. 0: COMP1 input is active low 1: COMP1 input is active high Note: This bit cannot be modified as long as LOCK level 1 has been programmed.
  [9] BK2INP — BRK2 BKIN2 input polarity This bit selects the BKIN2 input sensitivity. It must be programmed together with the BK2P polarity bit. 0: BKIN2 input is active low 1: BKIN2 input is active high Note: This bit cannot be modified as long as LOCK level 1 has been programmed.
  [2] BK2CMP2E — BRK2 COMP2 enable This bit enables the COMP2 for the timer’s BRK2 input. COMP2 output is ‘ORed’ with the other BRK2 sources. 0: COMP2 input disabled 1: COMP2 input enabled Note: This bit cannot be modified as long as LOCK level 1 has been programmed.
  [1] BK2CMP1E — BRK2 COMP1 enable This bit enables the COMP1 for the timer’s BRK2 input. COMP1 output is ‘ORed’ with the other BRK2 sources. 0: COMP1 input disabled 1: COMP1 input enabled Note: This bit cannot be modified as long as LOCK level 1 has been programmed.
  [0] BK2INE — BRK2 BKIN input enable This bit enables the BKIN2 input. BKIN2 input is ‘ORed’ with the other BRK2 sources. 0: BKIN2 input disabled 1: BKIN2 input enabled Note: This bit cannot be modified as long as LOCK level 1 has been programmed.
0x70 DBGSEL — Debug select register
  [2:0] DBGSEL — debug select
